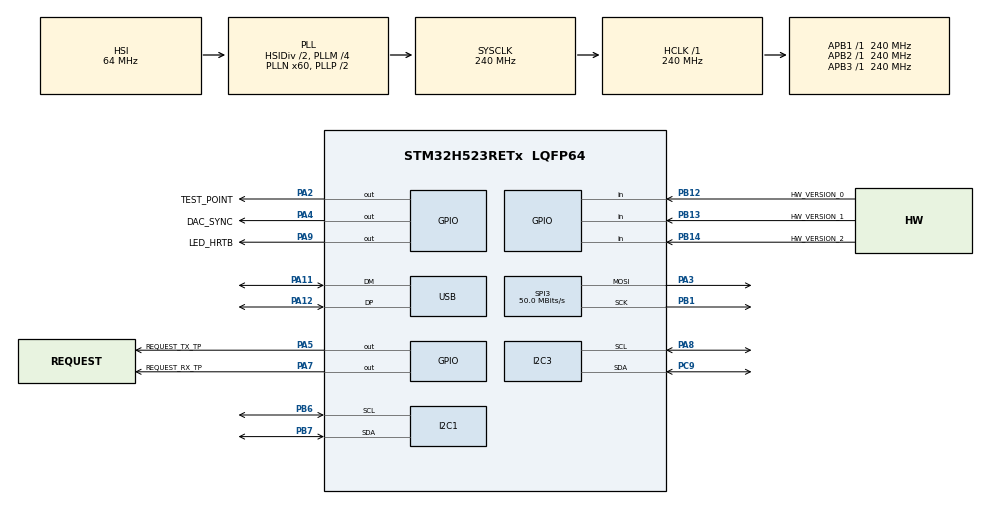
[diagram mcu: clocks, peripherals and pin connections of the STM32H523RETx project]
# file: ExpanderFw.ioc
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BOOTPATH.BootPathName=LEGACY
BOOTPATH.UserSelectedBootPath=LEGACY
CORTEX_M33_NS.userName=CORTEX_M33
GPDMA1.DESTINC_GPDMACH0=DMA_DINC_INCREMENTED
GPDMA1.DESTINC_GPDMACH2=DMA_DINC_INCREMENTED
GPDMA1.DIRECTION_GPDMACH1=DMA_MEMORY_TO_PERIPH
GPDMA1.DIRECTION_GPDMACH3=DMA_MEMORY_TO_PERIPH
GPDMA1.IPHANDLE_GPDMACH0-SIMPLEREQUEST_GPDMACH0=__NULL
GPDMA1.IPHANDLE_GPDMACH1-SIMPLEREQUEST_GPDMACH1=__NULL
GPDMA1.IPHANDLE_GPDMACH2-SIMPLEREQUEST_GPDMACH2=__NULL
GPDMA1.IPHANDLE_GPDMACH3-SIMPLEREQUEST_GPDMACH3=__NULL
GPDMA1.REQUEST_GPDMACH0=GPDMA1_REQUEST_I2C1_RX
GPDMA1.REQUEST_GPDMACH1=GPDMA1_REQUEST_I2C1_TX
GPDMA1.REQUEST_GPDMACH2=GPDMA1_REQUEST_I2C3_RX
GPDMA1.REQUEST_GPDMACH3=GPDMA1_REQUEST_I2C3_TX
GPDMA1.SRCINC_GPDMACH1=DMA_SINC_INCREMENTED
GPDMA1.SRCINC_GPDMACH3=DMA_SINC_INCREMENTED
I2C1.OwnAddress=1
I2C1.Timing=0x00707CBB
I2C3.OwnAddress=2
I2C3.Timing=0x00707CBB
Mcu.Family=STM32H5
Mcu.Name=STM32H523RETx
Mcu.Package=LQFP64
NVIC.GPDMA1_Channel0_IRQn=true\:0\:0\:false\:false\:true\:true\:false\:true\:true
NVIC.GPDMA1_Channel1_IRQn=true\:0\:0\:false\:false\:true\:true\:false\:true\:true
NVIC.GPDMA1_Channel2_IRQn=true\:0\:0\:false\:false\:true\:true\:false\:true\:true
NVIC.GPDMA1_Channel3_IRQn=true\:0\:0\:false\:false\:true\:true\:false\:true\:true
NVIC.I2C1_ER_IRQn=true\:0\:0\:false\:false\:true\:false\:true\:true\:true
NVIC.I2C1_EV_IRQn=true\:0\:0\:false\:false\:true\:false\:true\:true\:true
NVIC.I2C3_ER_IRQn=true\:0\:0\:false\:false\:true\:false\:true\:true\:true
NVIC.I2C3_EV_IRQn=true\:0\:0\:false\:false\:true\:false\:true\:true\:true
NVIC.PriorityGroup=NVIC_PRIORITYGROUP_4
NVIC.TIM5_IRQn=true\:0\:0\:false\:false\:true\:false\:true\:true\:true
NVIC.TIM6_IRQn=true\:15\:0\:false\:false\:true\:false\:false\:true\:true
NVIC.TimeBase=TIM6_IRQn
NVIC.TimeBaseIP=TIM6
NVIC.USB_DRD_FS_IRQn=true\:0\:0\:false\:false\:true\:false\:true\:true\:true
PA11.Mode=Device
PA11.Signal=USB_DM
PA12.Mode=Device
PA12.Signal=USB_DP
PA13(JTMS/SWDIO).Mode=Trace_Asynchronous_SW
PA13(JTMS/SWDIO).Signal=DEBUG_JTMS-SWDIO
PA14(JTCK/SWCLK).Mode=Trace_Asynchronous_SW
PA14(JTCK/SWCLK).Signal=DEBUG_JTCK-SWCLK
PA2.GPIO_Label=TEST_POINT
PA2.Signal=GPIO_Output
PA3.GPIO_Speed=GPIO_SPEED_FREQ_VERY_HIGH
PA3.Mode=TX_Only_Simplex_Unidirect_Master
PA3.Signal=SPI3_MOSI
PA4.GPIO_Label=DAC_SYNC
PA4.PinState=GPIO_PIN_SET
PA4.Signal=GPIO_Output
PA5.GPIO_Label=REQUEST_TX_TP
PA5.Signal=GPIO_Output
PA7.GPIO_Label=REQUEST_RX_TP
PA7.Signal=GPIO_Output
PA8.GPIO_Pu=GPIO_PULLUP
PA8.Mode=I2C
PA8.Signal=I2C3_SCL
PA9.GPIO_Label=LED_HRTB
PA9.Signal=GPIO_Output
PB1.GPIO_Speed=GPIO_SPEED_FREQ_VERY_HIGH
PB1.Mode=TX_Only_Simplex_Unidirect_Master
PB1.Signal=SPI3_SCK
PB12.GPIO_Label=HW_VERSION_0
PB12.GPIO_PuPd=GPIO_PULLDOWN
PB12.Signal=GPIO_Input
PB13.GPIO_Label=HW_VERSION_1
PB13.GPIO_PuPd=GPIO_PULLDOWN
PB13.Signal=GPIO_Input
PB14.GPIO_Label=HW_VERSION_2
PB14.GPIO_PuPd=GPIO_PULLDOWN
PB14.Signal=GPIO_Input
PB3(JTDO/TRACESWO).Mode=Trace_Asynchronous_SW
PB3(JTDO/TRACESWO).Signal=DEBUG_JTDO-SWO
PB6.GPIO_Pu=GPIO_PULLUP
PB6.Mode=I2C
PB6.Signal=I2C1_SCL
PB7.GPIO_Pu=GPIO_PULLUP
PB7.Mode=I2C
PB7.Signal=I2C1_SDA
PC9.GPIO_Pu=GPIO_PULLUP
PC9.Mode=I2C
PC9.Signal=I2C3_SDA
ProjectManager.HeapSize=0x200
ProjectManager.StackSize=0x400
ProjectManager.TargetToolchain=STM32CubeIDE
RAMCFG.Instance-BKPRAM_Activate=RAMCFG_BKPRAM
RCC.ADCFreq_Value=240000000
RCC.AHBFreq_Value=240000000
RCC.APB1Freq_Value=240000000
RCC.APB1TimFreq_Value=240000000
RCC.APB2Freq_Value=240000000
RCC.APB2TimFreq_Value=240000000
RCC.APB3Freq_Value=240000000
RCC.CSI_VALUE=4000000
RCC.CortexFreq_Value=240000000
RCC.EPOD_VALUE=32000000
RCC.HCLKFreq_Value=240000000
RCC.HSE_VALUE=25000000
RCC.HSI48_VALUE=48000000
RCC.HSI_VALUE=64000000
RCC.I2C1CLockSelection=RCC_I2C1CLKSOURCE_HSI
RCC.I2C3CLockSelection=RCC_I2C3CLKSOURCE_HSI
RCC.LSE_VALUE=32768
RCC.LSIRC_VALUE=32000
RCC.PLL2M=4
RCC.PLL2N=50
RCC.PLL2Q=4
RCC.PLL2Source=RCC_PLL2_SOURCE_HSI
RCC.PLL3M=4
RCC.PLL3N=50
RCC.PLL3P=4
RCC.PLL3Q=4
RCC.PLL3Source=RCC_PLL3_SOURCE_HSI
RCC.PLLM=4
RCC.PLLN=60
RCC.PLLSourceVirtual=RCC_PLL1_SOURCE_HSI
RCC.SPI1CLockSelection=RCC_SPI1CLKSOURCE_PLL2P
RCC.SPI3CLockSelection=RCC_SPI3CLKSOURCE_PLL2P
RCC.SPI4CLockSelection=RCC_SPI4CLKSOURCE_PLL2Q
RCC.SYSCLKFreq_VALUE=240000000
RCC.SYSCLKSource=RCC_SYSCLKSOURCE_PLLCLK
RCC.USBFreq_Value=48000000
RCC.VCOOutputFreq_Value=480000000
SPI3.BaudRatePrescaler=SPI_BAUDRATEPRESCALER_4
SPI3.CLKPhase=SPI_PHASE_1EDGE
SPI3.CLKPolarity=SPI_POLARITY_HIGH
SPI3.CalculateBaudRate=50.0 MBits/s
SPI3.DataSize=SPI_DATASIZE_8BIT
SPI3.Direction=SPI_DIRECTION_2LINES_TXONLY
SPI3.MasterKeepIOState=SPI_MASTER_KEEP_IO_STATE_ENABLE
SPI3.Mode=SPI_MODE_MASTER
SPI3.NSSPMode=SPI_NSS_PULSE_DISABLE
SPI3.VirtualType=VM_MASTER
THREADX.TX_APP_MEM_POOL_SIZE=32*1024
THREADX.TX_ENABLE_EVENT_TRACE=1
THREADX.TX_TIMER_TICKS_PER_SECOND=1000
TIM2.Prescaler=240
TIM5.PeriodNoDither=239
USB.VirtualMode=Device_Only
USBX.BSP.number=1
USBX.Core_System=1
USBX.MAX_POWER_IN_MILLI_AMPER=500
USBX.REG_USBX_DEVICE_CON_CK=0
USBX.USBD_CDCACM_EPINCMD_ADDR=2
USBX.USBD_CDCACM_EPIN_ADDR=1
USBX.USBD_MANUFACTURER_STRING=STMicroelectronics
USBX.USBD_PID=22288
USBX.USBD_PRODUCT_STRING=STM32 USB Device
USBX.USBD_SERIAL_NUMBER=EXPV1
USBX.USBX_DEVICE_SYS_SIZE=4*1024
USBX.UX_DEVICE_APP_MEM_POOL_SIZE=8*1024
USBX.UX_DEVICE_CDC_ACM=1
USBX.UX_DEVICE_CLASS_CDC_ACM_WRITE_AUTO_ZLP=1
USBX.UX_Device_Controller=1
USBX.UX_Device_CoreStack=1
USBX.UX_SLAVE_REQUEST_DATA_MAX_LENGTH=512
USBX0.BSP.STBoard=false
USBX0.BSP.api=Unknown
USBX0.BSP.instance=USB
USBX0.BSP.ip=USB
USBX0.BSP.mode=Device_Only
USBX0.BSP.name=USB_Device
USBX0.BSP.solution=USB
VP_BOOTPATH_VS_BOOTPATH.Mode=BP_Activate
VP_CORTEX_M33_NS_VS_Hclk.Mode=Hclk_Mode
VP_GPDMA1_VS_GPDMACH0.Mode=SIMPLEREQUEST_GPDMACH0
VP_GPDMA1_VS_GPDMACH1.Mode=SIMPLEREQUEST_GPDMACH1
VP_GPDMA1_VS_GPDMACH2.Mode=SIMPLEREQUEST_GPDMACH2
VP_GPDMA1_VS_GPDMACH3.Mode=SIMPLEREQUEST_GPDMACH3
VP_ICACHE_VS_ICACHE.Mode=DirectMappedCache
VP_MEMORYMAP_VS_MEMORYMAP.Mode=CurAppReg
VP_PWR_VS_DBSignals.Mode=DisableDeadBatterySignals
VP_PWR_VS_LPOM.Mode=PowerOptimisation
VP_PWR_VS_SECSignals.Mode=Security/Privilege
VP_RAMCFG_VS_BKPRAM.Mode=BKPRAM_Activate
VP_SYS_VS_tim6.Mode=TIM6
VP_THREADX_VS_RTOSJjThreadXJjCoreJjDefault.Mode=Core_Default
VP_THREADX_VS_RTOSJjThreadXJjTraceX_SupportJjDefault.Mode=TraceX_Support_Default
VP_TIM2_VS_ClockSourceINT.Mode=Internal
VP_TIM5_VS_ClockSourceINT.Mode=Internal
VP_USBX_Core_System.Mode=Core_System
VP_USBX_UX\ Device\ CDC\ ACM\ Class_FS.Mode=UX_Device_class_CDC_ACM_FS
VP_USBX_UX\ Device\ Controller_FS.Mode=UX_Device_Controller_FS
VP_USBX_UX\ Device\ CoreStack_FS.Mode=UX_Device_CoreStack_FS
board=custom

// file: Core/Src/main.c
/* USER CODE BEGIN Header */
/**
 ******************************************************************************
 * @file           : main.c
 * @brief          : Main program body
 ******************************************************************************
 * @attention
 *
 * Copyright (c) 2024 STMicroelectronics.
 * All rights reserved.
 *
 * This software is licensed under terms that can be found in the LICENSE file
 * in the root directory of this software component.
 * If no LICENSE file comes with this software, it is provided AS-IS.
 *
 ******************************************************************************
 */
/* USER CODE END Header */
#include "app_threadx.h"
#include "main.h"
#include "gpdma.h"
#include "i2c.h"
#include "icache.h"
#include "memorymap.h"
#include "ramcfg.h"
#include "spi.h"
#include "tim.h"
#include "usb.h"
#include "gpio.h"

/* USER CODE BEGIN Includes */
#include "util/c2cpp.hpp"
/* USER CODE END Includes */

/* USER CODE BEGIN PD */
#define RENAME_CUBEMX_MAIN
/* USER CODE END PD */

void SystemClock_Config(void);

/* USER CODE BEGIN 0 */
#ifdef RENAME_CUBEMX_MAIN
void initPeripherals() {
#else
/* USER CODE END 0 */

int main(void)
{

  /* USER CODE BEGIN 1 */
#endif
  /* USER CODE END 1 */

  /* MCU Configuration--------------------------------------------------------*/

  /* Reset of all peripherals, Initializes the Flash interface and the Systick. */
  HAL_Init();

  /* Configure the system clock */
  SystemClock_Config();

  /* Initialize all configured peripherals */
  MX_GPIO_Init();
  MX_GPDMA1_Init();
  MX_ICACHE_Init();
  MX_I2C1_Init();
  MX_I2C3_Init();
  MX_TIM2_Init();
  MX_RAMCFG_Init();
  MX_SPI3_Init();
  MX_TIM5_Init();
  /* USER CODE BEGIN 2 */
#ifdef RENAME_CUBEMX_MAIN
  return;
#else
  /* USER CODE END 2 */

  MX_ThreadX_Init();

  /* We should never get here as control is now taken by the scheduler */

  /* Infinite loop */
  while (1) {

    /* USER CODE BEGIN 3 */
  }
#endif
  /* USER CODE END 3 */
}

void SystemClock_Config(void)
{
  RCC_OscInitTypeDef RCC_OscInitStruct = {0};
  RCC_ClkInitTypeDef RCC_ClkInitStruct = {0};

  /** Configure the main internal regulator output voltage
  */
  __HAL_PWR_VOLTAGESCALING_CONFIG(PWR_REGULATOR_VOLTAGE_SCALE0);

  while(!__HAL_PWR_GET_FLAG(PWR_FLAG_VOSRDY)) {}

  /** Initializes the RCC Oscillators according to the specified parameters
  * in the RCC_OscInitTypeDef structure.
  */
  RCC_OscInitStruct.OscillatorType = RCC_OSCILLATORTYPE_HSI48|RCC_OSCILLATORTYPE_HSI;
  RCC_OscInitStruct.HSIState = RCC_HSI_ON;
  RCC_OscInitStruct.HSIDiv = RCC_HSI_DIV2;
  RCC_OscInitStruct.HSICalibrationValue = RCC_HSICALIBRATION_DEFAULT;
  RCC_OscInitStruct.HSI48State = RCC_HSI48_ON;
  RCC_OscInitStruct.PLL.PLLState = RCC_PLL_ON;
  RCC_OscInitStruct.PLL.PLLSource = RCC_PLL1_SOURCE_HSI;
  RCC_OscInitStruct.PLL.PLLM = 4;
  RCC_OscInitStruct.PLL.PLLN = 60;
  RCC_OscInitStruct.PLL.PLLP = 2;
  RCC_OscInitStruct.PLL.PLLQ = 2;
  RCC_OscInitStruct.PLL.PLLR = 2;
  RCC_OscInitStruct.PLL.PLLRGE = RCC_PLL1_VCIRANGE_3;
  RCC_OscInitStruct.PLL.PLLVCOSEL = RCC_PLL1_VCORANGE_WIDE;
  RCC_OscInitStruct.PLL.PLLFRACN = 0;
  if (HAL_RCC_OscConfig(&RCC_OscInitStruct) != HAL_OK)
  {
    Error_Handler();
  }

  /** Initializes the CPU, AHB and APB buses clocks
  */
  RCC_ClkInitStruct.ClockType = RCC_CLOCKTYPE_HCLK|RCC_CLOCKTYPE_SYSCLK
                              |RCC_CLOCKTYPE_PCLK1|RCC_CLOCKTYPE_PCLK2
                              |RCC_CLOCKTYPE_PCLK3;
  RCC_ClkInitStruct.SYSCLKSource = RCC_SYSCLKSOURCE_PLLCLK;
  RCC_ClkInitStruct.AHBCLKDivider = RCC_SYSCLK_DIV1;
  RCC_ClkInitStruct.APB1CLKDivider = RCC_HCLK_DIV1;
  RCC_ClkInitStruct.APB2CLKDivider = RCC_HCLK_DIV1;
  RCC_ClkInitStruct.APB3CLKDivider = RCC_HCLK_DIV1;

  if (HAL_RCC_ClockConfig(&RCC_ClkInitStruct, FLASH_LATENCY_5) != HAL_OK)
  {
    Error_Handler();
  }

  /** Configure the programming delay
  */
  __HAL_FLASH_SET_PROGRAM_DELAY(FLASH_PROGRAMMING_DELAY_2);
}

void HAL_TIM_PeriodElapsedCallback(TIM_HandleTypeDef *htim)
{
  /* USER CODE BEGIN Callback 0 */
  if (htim->Instance == TIM5) {
	  timerExpired();
  }

  /* USER CODE END Callback 0 */
  if (htim->Instance == TIM6) {
    HAL_IncTick();
  }
}

void Error_Handler(void)
{
  __disable_irq();
  while (1) {
  }
}
